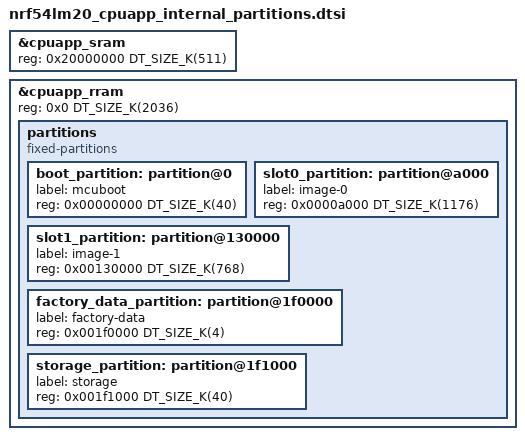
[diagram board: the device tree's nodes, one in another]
/*
 * Copyright (c) 2026 Nordic Semiconductor ASA
 *
 * SPDX-License-Identifier: LicenseRef-Nordic-5-Clause
 */

/delete-node/ &boot_partition;
/delete-node/ &slot0_partition;
/delete-node/ &slot1_partition;
/delete-node/ &storage_partition;

&cpuapp_sram {
	reg = <0x20000000 DT_SIZE_K(511)>;
	ranges = <0x0 0x20000000 DT_SIZE_K(511)>;
};

&cpuapp_rram {
	reg = <0x0 DT_SIZE_K(2036)>;

	partitions {
		compatible = "fixed-partitions";
		#address-cells = <1>;
		#size-cells = <1>;

		boot_partition: partition@0 {
			label = "mcuboot";
			reg = <0x00000000 DT_SIZE_K(40)>;
		};

		slot0_partition: partition@a000 {
			label = "image-0";
			reg = <0x0000a000 DT_SIZE_K(1176)>;
		};

		/* Compression ratio 34.75% */
		slot1_partition: partition@130000 {
			label = "image-1";
			reg = <0x00130000 DT_SIZE_K(768)>;
		};

		factory_data_partition: partition@1f0000 {
			label = "factory-data";
			reg = <0x001f0000 DT_SIZE_K(4)>;
		};

		storage_partition: partition@1f1000 {
			label = "storage";
			reg = <0x001f1000 DT_SIZE_K(40)>;
		};
	};
};
